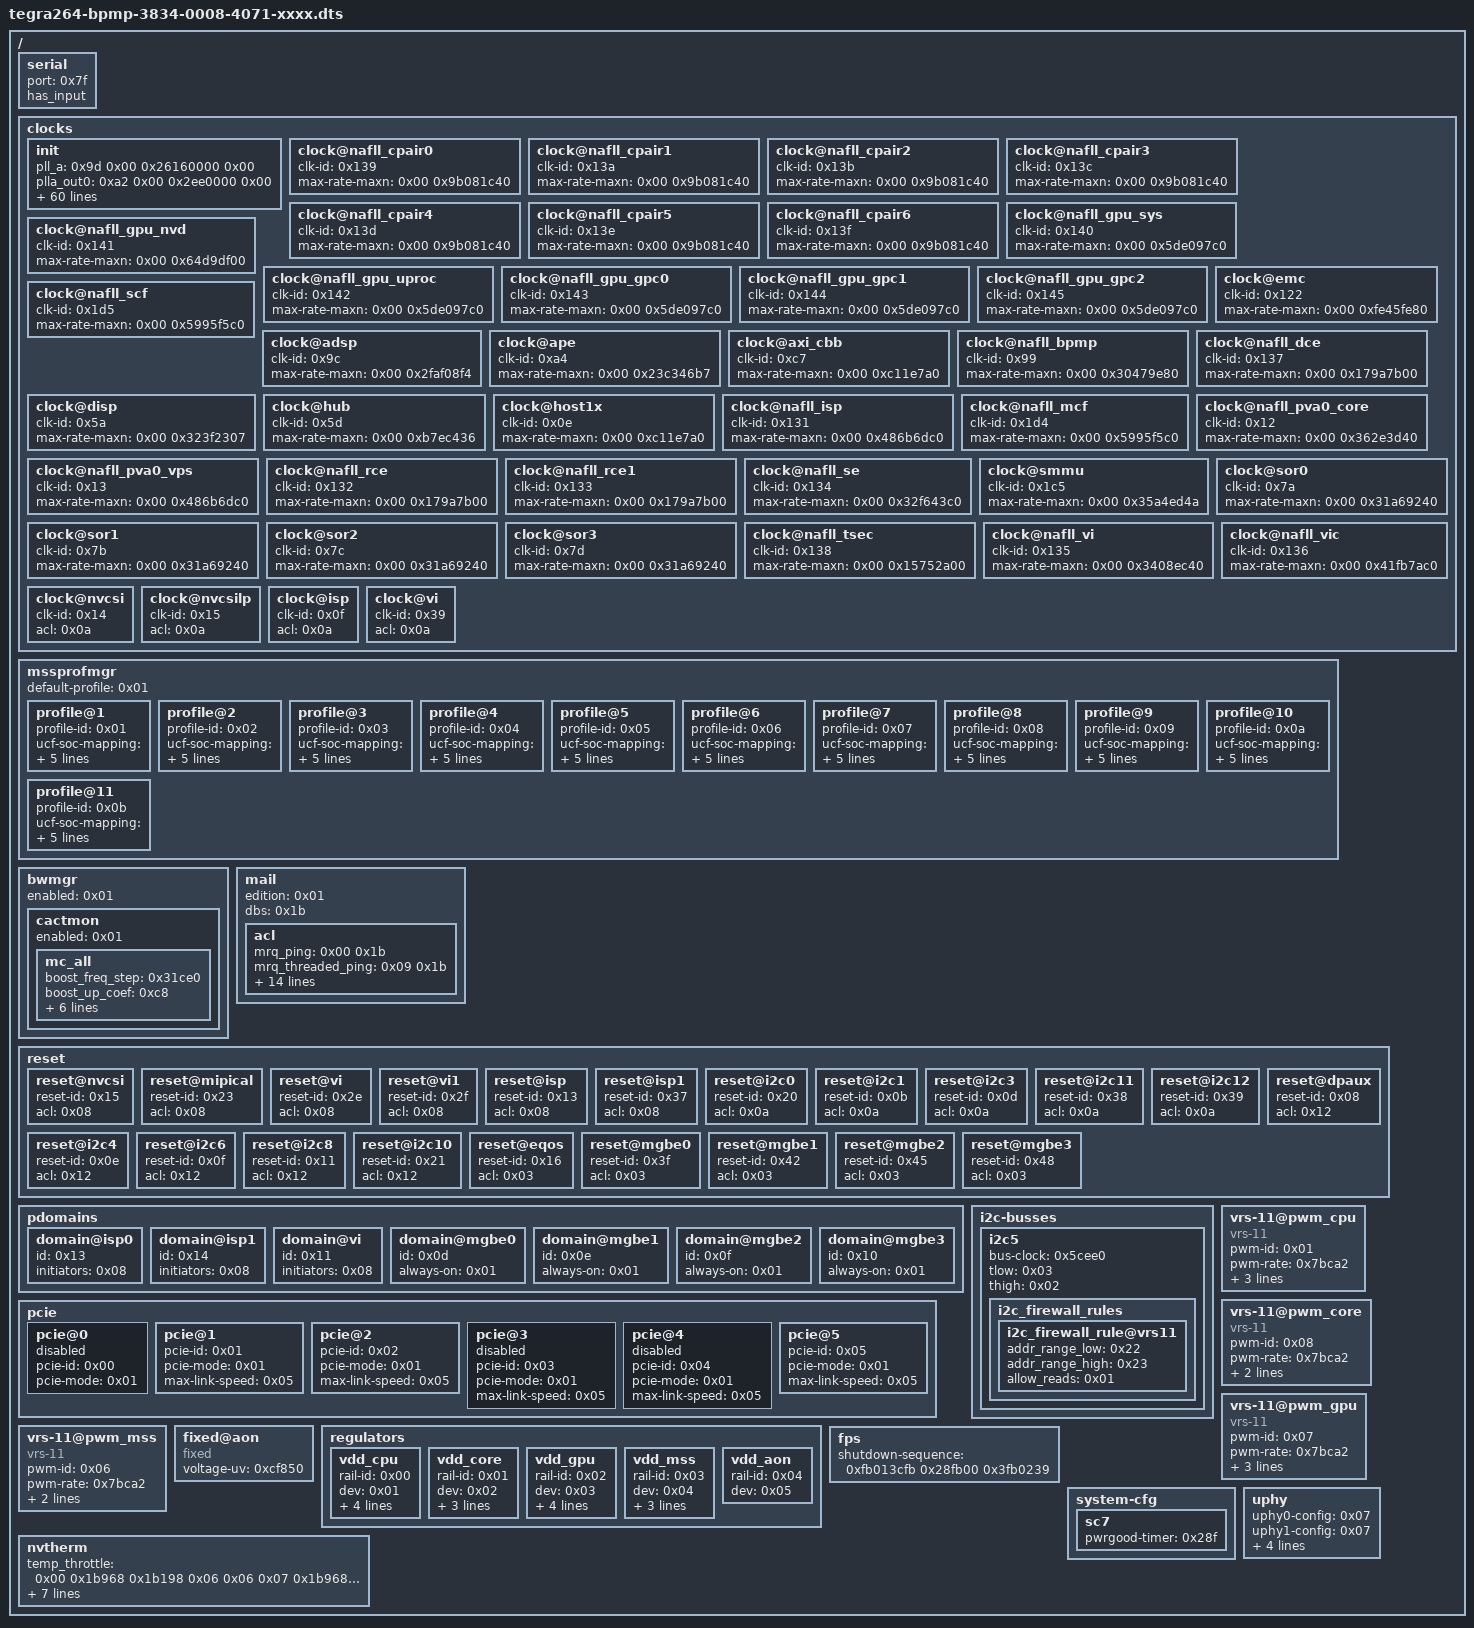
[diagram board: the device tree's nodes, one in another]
/dts-v1/;

/ {

	serial {
		port = <0x7f>;
		has_input;
	};

	clocks {

		init {
			pll_a = <0x9d 0x00 0x26160000 0x00>;
			plla_out0 = <0xa2 0x00 0x2ee0000 0x00>;
			pll_a1 = <0x9e 0x00 0x3a980000 0x00>;
			plla1_out1 = <0x9f 0x00 0x2ee0000 0x00>;
			pll_aon = <0xa0 0x00 0x23c34600 0x00>;
			pll_hub1 = <0x1c6 0x00 0x2faf0800 0x00>;
			pll_nvcsi = <0x12b 0x00 0xffffffff 0x00>;
			pllrefgp_out = <0x1b5 0x00 0x4a817c80 0x00>;
			qspi0 = <0x1f 0x00 0x00 0x04>;
			uart0 = <0x32 0x00 0x00 0x04>;
			uart10 = <0x33 0x00 0x00 0x04>;
			se_root = <0x29 0x134 0xffffffff 0x00>;
			se_clk = <0x25 0x00 0x00 0x04>;
			seu2_clk = <0x27 0x00 0x00 0x04>;
			seu3_clk = <0x28 0x00 0x00 0x04>;
			rdet_clk = <0x159 0x00 0x00 0x04>;
			adsp = <0x9c 0x9d 0x26160000 0x00>;
			ahub = <0xa3 0xa1 0x5f5e100 0x00>;
			aon_cpu = <0xc4 0xa0 0x23c34600 0x00>;
			aon_nic = <0xc5 0xa0 0x11e1a300 0x00>;
			ape = <0xa4 0xa1 0x11e1a300 0x00>;
			aud_mclk = <0x115 0x9f 0x00 0x00>;
			axi_cbb = <0xc7 0x9a 0x1823cf40 0x00>;
			aza_2xbit = <0x8f 0x06 0x66ff300 0x00>;
			csite = <0xca 0x00 0x00 0x04>;
			hcsite = <0xcb 0x00 0x00 0x04>;
			dbb_uphy0_0 = <0x1ad 0x00 0x00 0x02>;
			dbb_uphy0_1 = <0x1ad 0x1b5 0x4a817c80 0x00>;
			dce_cpu = <0x90 0x137 0xffffffff 0x00>;
			dmic1 = <0xc1 0x9f 0x00 0x00>;
			dmic1_audio_sync = <0xb6 0xa5 0x00 0x00>;
			dmic5 = <0xc2 0xa2 0x00 0x00>;
			dspk1 = <0xc3 0x9f 0x00 0x00>;
			dspk1_audio_sync = <0xb7 0xa5 0x00 0x00>;
			extperiph1 = <0x116 0x16 0x16b76e0 0x00>;
			extperiph2 = <0x117 0x16 0x16b76e0 0x00>;
			i2s1 = <0xb8 0x9f 0x00 0x00>;
			i2s2 = <0xb9 0x9f 0x00 0x00>;
			i2s3 = <0xba 0x9f 0x00 0x00>;
			i2s4 = <0xbb 0x9f 0x00 0x00>;
			i2s5 = <0xbc 0x9f 0x00 0x00>;
			i2s6 = <0xbd 0x9f 0x00 0x00>;
			i2s7 = <0xbe 0x9f 0x00 0x00>;
			i2s8 = <0xbf 0x9f 0x00 0x00>;
			i2s9 = <0xc0 0xa2 0x00 0x00>;
			isp_root = <0x11 0x131 0xffffffff 0x00>;
			maud = <0x8e 0x16 0xc11e7a0 0x00>;
			nvcsi = <0x14 0x12b 0x00 0x00>;
			nvcsilp = <0x15 0x09 0x00 0x00>;
			pva0_cpu_axi = <0x17 0x12 0xffffffff 0x00>;
			pva0_vps = <0x18 0x13 0xffffffff 0x00>;
			rce_cpu = <0x23 0x132 0xffffffff 0x00>;
			vi_root = <0x3c 0x135 0xffffffff 0x00>;
			vic = <0x3b 0x136 0xffffffff 0x00>;
			xusb1_core = <0x101 0x16 0x608f3d0 0x00>;
			xusb1_falcon = <0x102 0x130 0x1c9c3800 0x00>;
			xusb1_fs = <0x103 0x12e 0x2dc6c00 0x00>;
			xusb1_ss = <0x104 0x130 0x7270e00 0x00>;
			emc = <0x122 0x00 0xffffffff 0x00>;
			mcf = <0x1c7 0x00 0xffffffff 0x00>;
			scf = <0x1c8 0x00 0xffffffff 0x00>;
			smmu = <0x1c5 0x1c6 0x2faf0800 0x00>;
		};

		clock@nafll_cpair0 {
			clk-id = <0x139>;
			max-rate-maxn = <0x00 0x9b081c40>;
		};

		clock@nafll_cpair1 {
			clk-id = <0x13a>;
			max-rate-maxn = <0x00 0x9b081c40>;
		};

		clock@nafll_cpair2 {
			clk-id = <0x13b>;
			max-rate-maxn = <0x00 0x9b081c40>;
		};

		clock@nafll_cpair3 {
			clk-id = <0x13c>;
			max-rate-maxn = <0x00 0x9b081c40>;
		};

		clock@nafll_cpair4 {
			clk-id = <0x13d>;
			max-rate-maxn = <0x00 0x9b081c40>;
		};

		clock@nafll_cpair5 {
			clk-id = <0x13e>;
			max-rate-maxn = <0x00 0x9b081c40>;
		};

		clock@nafll_cpair6 {
			clk-id = <0x13f>;
			max-rate-maxn = <0x00 0x9b081c40>;
		};

		clock@nafll_gpu_sys {
			clk-id = <0x140>;
			max-rate-maxn = <0x00 0x5de097c0>;
		};

		clock@nafll_gpu_nvd {
			clk-id = <0x141>;
			max-rate-maxn = <0x00 0x64d9df00>;
		};

		clock@nafll_gpu_uproc {
			clk-id = <0x142>;
			max-rate-maxn = <0x00 0x5de097c0>;
		};

		clock@nafll_gpu_gpc0 {
			clk-id = <0x143>;
			max-rate-maxn = <0x00 0x5de097c0>;
		};

		clock@nafll_gpu_gpc1 {
			clk-id = <0x144>;
			max-rate-maxn = <0x00 0x5de097c0>;
		};

		clock@nafll_gpu_gpc2 {
			clk-id = <0x145>;
			max-rate-maxn = <0x00 0x5de097c0>;
		};

		clock@emc {
			clk-id = <0x122>;
			max-rate-maxn = <0x00 0xfe45fe80>;
		};

		clock@nafll_scf {
			clk-id = <0x1d5>;
			max-rate-maxn = <0x00 0x5995f5c0>;
		};

		clock@adsp {
			clk-id = <0x9c>;
			max-rate-maxn = <0x00 0x2faf08f4>;
		};

		clock@ape {
			clk-id = <0xa4>;
			max-rate-maxn = <0x00 0x23c346b7>;
		};

		clock@axi_cbb {
			clk-id = <0xc7>;
			max-rate-maxn = <0x00 0xc11e7a0>;
		};

		clock@nafll_bpmp {
			clk-id = <0x99>;
			max-rate-maxn = <0x00 0x30479e80>;
		};

		clock@nafll_dce {
			clk-id = <0x137>;
			max-rate-maxn = <0x00 0x179a7b00>;
		};

		clock@disp {
			clk-id = <0x5a>;
			max-rate-maxn = <0x00 0x323f2307>;
		};

		clock@hub {
			clk-id = <0x5d>;
			max-rate-maxn = <0x00 0xb7ec436>;
		};

		clock@host1x {
			clk-id = <0x0e>;
			max-rate-maxn = <0x00 0xc11e7a0>;
		};

		clock@nafll_isp {
			clk-id = <0x131>;
			max-rate-maxn = <0x00 0x486b6dc0>;
		};

		clock@nafll_mcf {
			clk-id = <0x1d4>;
			max-rate-maxn = <0x00 0x5995f5c0>;
		};

		clock@nafll_pva0_core {
			clk-id = <0x12>;
			max-rate-maxn = <0x00 0x362e3d40>;
		};

		clock@nafll_pva0_vps {
			clk-id = <0x13>;
			max-rate-maxn = <0x00 0x486b6dc0>;
		};

		clock@nafll_rce {
			clk-id = <0x132>;
			max-rate-maxn = <0x00 0x179a7b00>;
		};

		clock@nafll_rce1 {
			clk-id = <0x133>;
			max-rate-maxn = <0x00 0x179a7b00>;
		};

		clock@nafll_se {
			clk-id = <0x134>;
			max-rate-maxn = <0x00 0x32f643c0>;
		};

		clock@smmu {
			clk-id = <0x1c5>;
			max-rate-maxn = <0x00 0x35a4ed4a>;
		};

		clock@sor0 {
			clk-id = <0x7a>;
			max-rate-maxn = <0x00 0x31a69240>;
		};

		clock@sor1 {
			clk-id = <0x7b>;
			max-rate-maxn = <0x00 0x31a69240>;
		};

		clock@sor2 {
			clk-id = <0x7c>;
			max-rate-maxn = <0x00 0x31a69240>;
		};

		clock@sor3 {
			clk-id = <0x7d>;
			max-rate-maxn = <0x00 0x31a69240>;
		};

		clock@nafll_tsec {
			clk-id = <0x138>;
			max-rate-maxn = <0x00 0x15752a00>;
		};

		clock@nafll_vi {
			clk-id = <0x135>;
			max-rate-maxn = <0x00 0x3408ec40>;
		};

		clock@nafll_vic {
			clk-id = <0x136>;
			max-rate-maxn = <0x00 0x41fb7ac0>;
		};

		clock@nvcsi {
			clk-id = <0x14>;
			acl = <0x0a>;
		};

		clock@nvcsilp {
			clk-id = <0x15>;
			acl = <0x0a>;
		};

		clock@isp {
			clk-id = <0x0f>;
			acl = <0x0a>;
		};

		clock@vi {
			clk-id = <0x39>;
			acl = <0x0a>;
		};
	};

	mssprofmgr {
		default-profile = <0x01>;

		profile@1 {
			profile-id = <0x01>;
			ucf-soc-mapping = <0x00 0x2d98f940 0x00 0x757b12c0 0x00 0x757b12c0 0x00 0x757b12c0 0x00 0x757b12c0 0x00 0x757b12c0 0x00 0x757b12c0 0x00 0x757b12c0>;
			ucf-slc-mapping = <0x00 0x337f9800 0x00 0x6df87740 0x00 0x6df87740 0x00 0x6df87740 0x00 0x6df87740 0x00 0x6df87740 0x00 0x6df87740 0x00 0x6df87740>;
			smmu-mapping = <0x00 0x17d78400 0x00 0x35a4e900 0x00 0x35a4e900 0x00 0x35a4e900 0x00 0x35a4e900 0x00 0x35a4e900 0x00 0x35a4e900 0x00 0x35a4e900>;
		};

		profile@2 {
			profile-id = <0x02>;
			ucf-soc-mapping = <0x00 0x757b12c0 0x00 0x757b12c0 0x00 0x757b12c0 0x00 0x757b12c0 0x00 0x757b12c0 0x00 0x757b12c0 0x00 0x757b12c0 0x00 0x757b12c0>;
			ucf-slc-mapping = <0x00 0x6df87740 0x00 0x6df87740 0x00 0x6df87740 0x00 0x6df87740 0x00 0x6df87740 0x00 0x6df87740 0x00 0x6df87740 0x00 0x6df87740>;
			smmu-mapping = <0x00 0x4ca6cd80 0x00 0x4ca6cd80 0x00 0x4ca6cd80 0x00 0x4ca6cd80 0x00 0x4ca6cd80 0x00 0x4ca6cd80 0x00 0x4ca6cd80 0x00 0x4ca6cd80>;
		};

		profile@3 {
			profile-id = <0x03>;
			ucf-soc-mapping = <0x00 0x17d78400 0x00 0x17d78400 0x00 0x17d78400 0x00 0x17d78400 0x00 0x17d78400 0x00 0x22551000 0x00 0x315a4700 0x00 0x3e3a2d00>;
			ucf-slc-mapping = <0x00 0x17d78400 0x00 0x17d78400 0x00 0x17d78400 0x00 0x17d78400 0x00 0x1b5bc8c0 0x00 0x27b25a80 0x00 0x38538e40 0x00 0x45337440>;
			smmu-mapping = <0x00 0x20c85580 0x00 0x20c85580 0x00 0x20c85580 0x00 0x20c85580 0x00 0x20c85580 0x00 0x2cb41780 0x00 0x2cb41780 0x00 0x35a4e900>;
		};

		profile@4 {
			profile-id = <0x04>;
			ucf-soc-mapping = <0x00 0x757b12c0 0x00 0x757b12c0 0x00 0x757b12c0 0x00 0x757b12c0 0x00 0x757b12c0 0x00 0x757b12c0 0x00 0x757b12c0 0x00 0x757b12c0>;
			ucf-slc-mapping = <0x00 0x17d78400 0x00 0x17d78400 0x00 0x17d78400 0x00 0x47868c00 0x00 0x47868c00 0x00 0x47868c00 0x00 0x47868c00 0x00 0x59682f00>;
			smmu-mapping = <0x00 0x20c85580 0x00 0x20c85580 0x00 0x26be3680 0x00 0x26be3680 0x00 0x26be3680 0x00 0x26be3680 0x00 0x2cb41780 0x00 0x35a4e900>;
		};

		profile@5 {
			profile-id = <0x05>;
			ucf-soc-mapping = <0x00 0x17d78400 0x00 0x17d78400 0x00 0x17d78400 0x00 0x47868c00 0x00 0x47868c00 0x00 0x47868c00 0x00 0x47868c00 0x00 0x59682f00>;
			ucf-slc-mapping = <0x00 0x6df87740 0x00 0x6df87740 0x00 0x6df87740 0x00 0x6df87740 0x00 0x6df87740 0x00 0x6df87740 0x00 0x6df87740 0x00 0x6df87740>;
			smmu-mapping = <0x00 0x20c85580 0x00 0x20c85580 0x00 0x26be3680 0x00 0x26be3680 0x00 0x26be3680 0x00 0x26be3680 0x00 0x2cb41780 0x00 0x35a4e900>;
		};

		profile@6 {
			profile-id = <0x06>;
			ucf-soc-mapping = <0x00 0x17d78400 0x00 0x17d78400 0x00 0x17d78400 0x00 0x47868c00 0x00 0x47868c00 0x00 0x47868c00 0x00 0x47868c00 0x00 0x59682f00>;
			ucf-slc-mapping = <0x00 0x17d78400 0x00 0x17d78400 0x00 0x17d78400 0x00 0x47868c00 0x00 0x47868c00 0x00 0x47868c00 0x00 0x47868c00 0x00 0x59682f00>;
			smmu-mapping = <0x00 0x4ca6cd80 0x00 0x4ca6cd80 0x00 0x4ca6cd80 0x00 0x4ca6cd80 0x00 0x4ca6cd80 0x00 0x4ca6cd80 0x00 0x4ca6cd80 0x00 0x4ca6cd80>;
		};

		profile@7 {
			profile-id = <0x07>;
			ucf-soc-mapping = <0x00 0x47868c00 0x00 0x47868c00 0x00 0x47868c00 0x00 0x47868c00 0x00 0x47868c00 0x00 0x47868c00 0x00 0x47868c00 0x00 0x47868c00>;
			ucf-slc-mapping = <0x00 0x47868c00 0x00 0x47868c00 0x00 0x47868c00 0x00 0x47868c00 0x00 0x47868c00 0x00 0x47868c00 0x00 0x47868c00 0x00 0x47868c00>;
			smmu-mapping = <0x00 0x202fbf00 0x00 0x202fbf00 0x00 0x202fbf00 0x00 0x202fbf00 0x00 0x202fbf00 0x00 0x202fbf00 0x00 0x202fbf00 0x00 0x202fbf00>;
		};

		profile@8 {
			profile-id = <0x08>;
			ucf-soc-mapping = <0x00 0x59682f00 0x00 0x59682f00 0x00 0x59682f00 0x00 0x59682f00 0x00 0x59682f00 0x00 0x59682f00 0x00 0x59682f00 0x00 0x59682f00>;
			ucf-slc-mapping = <0x00 0x59682f00 0x00 0x59682f00 0x00 0x59682f00 0x00 0x59682f00 0x00 0x59682f00 0x00 0x59682f00 0x00 0x59682f00 0x00 0x59682f00>;
			smmu-mapping = <0x00 0x2cb41780 0x00 0x2cb41780 0x00 0x2cb41780 0x00 0x2cb41780 0x00 0x2cb41780 0x00 0x2cb41780 0x00 0x2cb41780 0x00 0x2cb41780>;
		};

		profile@9 {
			profile-id = <0x09>;
			ucf-soc-mapping = <0x00 0x69618a00 0x00 0x69618a00 0x00 0x69618a00 0x00 0x69618a00 0x00 0x69618a00 0x00 0x69618a00 0x00 0x69618a00 0x00 0x69618a00>;
			ucf-slc-mapping = <0x00 0x69618a00 0x00 0x69618a00 0x00 0x69618a00 0x00 0x69618a00 0x00 0x69618a00 0x00 0x69618a00 0x00 0x69618a00 0x00 0x69618a00>;
			smmu-mapping = <0x00 0x2cb41780 0x00 0x2cb41780 0x00 0x2cb41780 0x00 0x2cb41780 0x00 0x2cb41780 0x00 0x2cb41780 0x00 0x2cb41780 0x00 0x2cb41780>;
		};

		profile@10 {
			profile-id = <0x0a>;
			ucf-soc-mapping = <0x00 0x45613b00 0x00 0x45613b00 0x00 0x45613b00 0x00 0x45613b00 0x00 0x45613b00 0x00 0x45613b00 0x00 0x45613b00 0x00 0x45613b00>;
			ucf-slc-mapping = <0x00 0x45613b00 0x00 0x45613b00 0x00 0x45613b00 0x00 0x45613b00 0x00 0x45613b00 0x00 0x45613b00 0x00 0x45613b00 0x00 0x45613b00>;
			smmu-mapping = <0x00 0x2cb41780 0x00 0x2cb41780 0x00 0x2cb41780 0x00 0x2cb41780 0x00 0x2cb41780 0x00 0x2cb41780 0x00 0x2cb41780 0x00 0x2cb41780>;
		};

		profile@11 {
			profile-id = <0x0b>;
			ucf-soc-mapping = <0x00 0x17d78400 0x00 0x17d78400 0x00 0x17d78400 0x00 0x17d78400 0x00 0x17d78400 0x00 0x17d78400 0x00 0x17d78400 0x00 0x17d78400>;
			ucf-slc-mapping = <0x00 0x17d78400 0x00 0x17d78400 0x00 0x17d78400 0x00 0x17d78400 0x00 0x17d78400 0x00 0x17d78400 0x00 0x17d78400 0x00 0x17d78400>;
			smmu-mapping = <0x00 0x2cb41780 0x00 0x2cb41780 0x00 0x2cb41780 0x00 0x2cb41780 0x00 0x2cb41780 0x00 0x2cb41780 0x00 0x2cb41780 0x00 0x2cb41780>;
		};
	};

	bwmgr {
		enabled = <0x01>;

		cactmon {
			enabled = <0x01>;

			mc_all {
				boost_freq_step = <0x31ce0>;
				boost_up_coef = <0xc8>;
				boost_down_coef = <0x32>;
				boost_up_threshold = <0x1e>;
				boost_down_threshold = <0x14>;
				up_wmark_window = <0x02>;
				down_wmark_window = <0x01>;
				avg_window_log2 = <0x05>;
			};
		};
	};

	mail {
		edition = <0x01>;
		dbs = <0x1b>;

		acl {
			mrq_ping = <0x00 0x1b>;
			mrq_threaded_ping = <0x09 0x1b>;
			mrq_reset = <0x14 0x1b>;
			mrq_i2c = <0x15 0x02>;
			mrq_clk = <0x16 0x1b>;
			mrq_query_abi = <0x17 0x1b>;
			mrq_thermal = <0x1b 0x02>;
			mrq_abi_ratchet = <0x1d 0x02>;
			mrq_emc_dvfs_latency = <0x1f 0x12>;
			mrq_pg = <0x42 0x1b>;
			mrq_cpu_ndiv_limits = <0x43 0x02>;
			mrq_strap = <0x44 0x02>;
			mrq_uphy = <0x45 0x02>;
			mrq_query_fw_tag = <0x47 0x1b>;
			mrq_fmon = <0x48 0x02>;
			mrq_debug = <0x4b 0x02>;
		};
	};

	reset {

		reset@nvcsi {
			reset-id = <0x15>;
			acl = <0x08>;
		};

		reset@mipical {
			reset-id = <0x23>;
			acl = <0x08>;
		};

		reset@vi {
			reset-id = <0x2e>;
			acl = <0x08>;
		};

		reset@vi1 {
			reset-id = <0x2f>;
			acl = <0x08>;
		};

		reset@isp {
			reset-id = <0x13>;
			acl = <0x08>;
		};

		reset@isp1 {
			reset-id = <0x37>;
			acl = <0x08>;
		};

		reset@i2c0 {
			reset-id = <0x20>;
			acl = <0x0a>;
		};

		reset@i2c1 {
			reset-id = <0x0b>;
			acl = <0x0a>;
		};

		reset@i2c3 {
			reset-id = <0x0d>;
			acl = <0x0a>;
		};

		reset@i2c11 {
			reset-id = <0x38>;
			acl = <0x0a>;
		};

		reset@i2c12 {
			reset-id = <0x39>;
			acl = <0x0a>;
		};

		reset@dpaux {
			reset-id = <0x08>;
			acl = <0x12>;
		};

		reset@i2c4 {
			reset-id = <0x0e>;
			acl = <0x12>;
		};

		reset@i2c6 {
			reset-id = <0x0f>;
			acl = <0x12>;
		};

		reset@i2c8 {
			reset-id = <0x11>;
			acl = <0x12>;
		};

		reset@i2c10 {
			reset-id = <0x21>;
			acl = <0x12>;
		};

		reset@eqos {
			reset-id = <0x16>;
			acl = <0x03>;
		};

		reset@mgbe0 {
			reset-id = <0x3f>;
			acl = <0x03>;
		};

		reset@mgbe1 {
			reset-id = <0x42>;
			acl = <0x03>;
		};

		reset@mgbe2 {
			reset-id = <0x45>;
			acl = <0x03>;
		};

		reset@mgbe3 {
			reset-id = <0x48>;
			acl = <0x03>;
		};
	};

	pdomains {

		domain@isp0 {
			id = <0x13>;
			initiators = <0x08>;
		};

		domain@isp1 {
			id = <0x14>;
			initiators = <0x08>;
		};

		domain@vi {
			id = <0x11>;
			initiators = <0x08>;
		};

		domain@mgbe0 {
			id = <0x0d>;
			always-on = <0x01>;
		};

		domain@mgbe1 {
			id = <0x0e>;
			always-on = <0x01>;
		};

		domain@mgbe2 {
			id = <0x0f>;
			always-on = <0x01>;
		};

		domain@mgbe3 {
			id = <0x10>;
			always-on = <0x01>;
		};
	};

	i2c-busses {

		i2c5 {
			bus-clock = <0x5cee0>;
			tlow = <0x03>;
			thigh = <0x02>;

			i2c_firewall_rules {

				i2c_firewall_rule@vrs11 {
					addr_range_low = <0x22>;
					addr_range_high = <0x23>;
					allow_reads = <0x01>;
				};
			};
		};
	};

	pcie {

		pcie@0 { // PCIe C0 RP
			status = "disabled";
			pcie-id = <0x00>;
			pcie-mode = <0x01>;
		};

		pcie@1 { // PCIe C1 RP
			status = "okay";
			pcie-id = <0x01>;
			pcie-mode = <0x01>;
			max-link-speed = <0x05>;
		};

		pcie@2 { // PCIe C2 RP - PCIe C2 EP
			status = "okay";
			pcie-id = <0x02>;
			pcie-mode = <0x01>;
			max-link-speed = <0x05>;
		};

		pcie@3 { // PCIe C3 RP
			status = "disabled";
			pcie-id = <0x03>;
			pcie-mode = <0x01>;
			max-link-speed = <0x05>;
		};

		pcie@4 { // PCIe C4 RP - PCIe C4 EP
			status = "disabled";
			pcie-id = <0x04>;
			pcie-mode = <0x01>;
			max-link-speed = <0x05>;
		};

		pcie@5 { // PCIe C5 RP - PCIe C5 EP
			status = "okay";
			pcie-id = <0x05>;
			pcie-mode = <0x01>;
			max-link-speed = <0x05>;
		};
	};

	vrs-11@pwm_cpu {
		compatible = "vrs-11";
		pwm-id = <0x01>;
		pwm-rate = <0x7bca2>;
		slave-address = <0x23>;
		channel = <0x00>;
		enable-gpio = <0x38>;
		phandle = <0x01>;
	};

	vrs-11@pwm_core {
		compatible = "vrs-11";
		pwm-id = <0x08>;
		pwm-rate = <0x7bca2>;
		slave-address = <0x23>;
		channel = <0x01>;
		phandle = <0x02>;
	};

	vrs-11@pwm_gpu {
		compatible = "vrs-11";
		pwm-id = <0x07>;
		pwm-rate = <0x7bca2>;
		slave-address = <0x22>;
		channel = <0x00>;
		enable-gpio = <0x39>;
		phandle = <0x03>;
	};

	vrs-11@pwm_mss {
		compatible = "vrs-11";
		pwm-id = <0x06>;
		pwm-rate = <0x7bca2>;
		slave-address = <0x22>;
		channel = <0x01>;
		phandle = <0x04>;
	};

	fixed@aon {
		compatible = "fixed";
		voltage-uv = <0xcf850>;
		phandle = <0x05>;
	};

	regulators {

		vdd_cpu {
			rail-id = <0x00>;
			dev = <0x01>;
			regulator-ramp-delay-linear = <0x1388>;
			regulator-enable-ramp-delay = <0xbb8>;
			regulator-min-microvolt = <0x927c0>;
			regulator-max-microvolt = <0x10c8e0>;
		};

		vdd_core {
			rail-id = <0x01>;
			dev = <0x02>;
			regulator-ramp-delay-linear = <0x1388>;
			regulator-min-microvolt = <0x927c0>;
			regulator-max-microvolt = <0x10c8e0>;
		};

		vdd_gpu {
			rail-id = <0x02>;
			dev = <0x03>;
			regulator-ramp-delay-linear = <0x1388>;
			regulator-enable-ramp-delay = <0xbb8>;
			regulator-min-microvolt = <0x927c0>;
			regulator-max-microvolt = <0x10c8e0>;
		};

		vdd_mss {
			rail-id = <0x03>;
			dev = <0x04>;
			regulator-ramp-delay-linear = <0x1388>;
			regulator-min-microvolt = <0x927c0>;
			regulator-max-microvolt = <0x10c8e0>;
		};

		vdd_aon {
			rail-id = <0x04>;
			dev = <0x05>;
		};
	};

	fps {
		shutdown-sequence = <0xfb013cfb 0x28fb00 0x3fb0239>;
	};

	system-cfg {

		sc7 {
			pwrgood-timer = <0x28f>;
		};
	};

	nvtherm {
		temp_throttle = <0x00 0x1b968 0x1b198 0x06 0x06 0x07 0x1b968 0x1b198 0x06 0x06 0x08 0x1b968 0x1b198 0x06 0x06 0x09 0x1b968 0x1b198 0x06 0x06 0x0a 0x1b968 0x1b198 0x06 0x06>;
		oc_throttle = <0x00 0x00 0x00 0x00 0x00 0x01 0x01 0x06 0x06 0x00 0x02 0x01 0x02 0x02 0x00>;
		thermtrip_hot = <0x1c138>;
		thermtrip_cold = <0xffff5808>;
		consistency_thresh = <0x11170>;
		bjt_offsets = <0x00 0x00 0x00 0x00 0x00 0x00 0x00 0x5dc 0x00 0x00 0x00 0x00 0x00 0x00 0x5dc 0xdac 0x00 0x00 0x00 0x00 0x00 0x00 0x00 0x00 0x3e8 0x2ee 0xfa 0xfa 0x2ee 0x1f4 0x1f4 0x2ee 0xfa 0x1f4 0x1f4 0x00 0x00 0x3e8 0x2ee 0xfa 0x4e2 0x3e8 0x4e2 0xfa 0x1f4 0x1f4 0x1f4 0x3e8 0x3e8 0x5dc 0x4e2 0x4e2 0xfa 0x4e2 0x3e8 0x7d0 0x5dc 0x00 0x1f4 0x3e8 0x7d0 0x5dc 0x5dc>;
	};

	uphy {
		status = "okay";
		uphy0-config = <0x07>;
		uphy1-config = <0x07>;
		mgbe0-speed = <0x02>;
		mgbe1-speed = <0x02>;
		mgbe2-speed = <0x02>;
		mgbe3-speed = <0x02>;
	};
};
